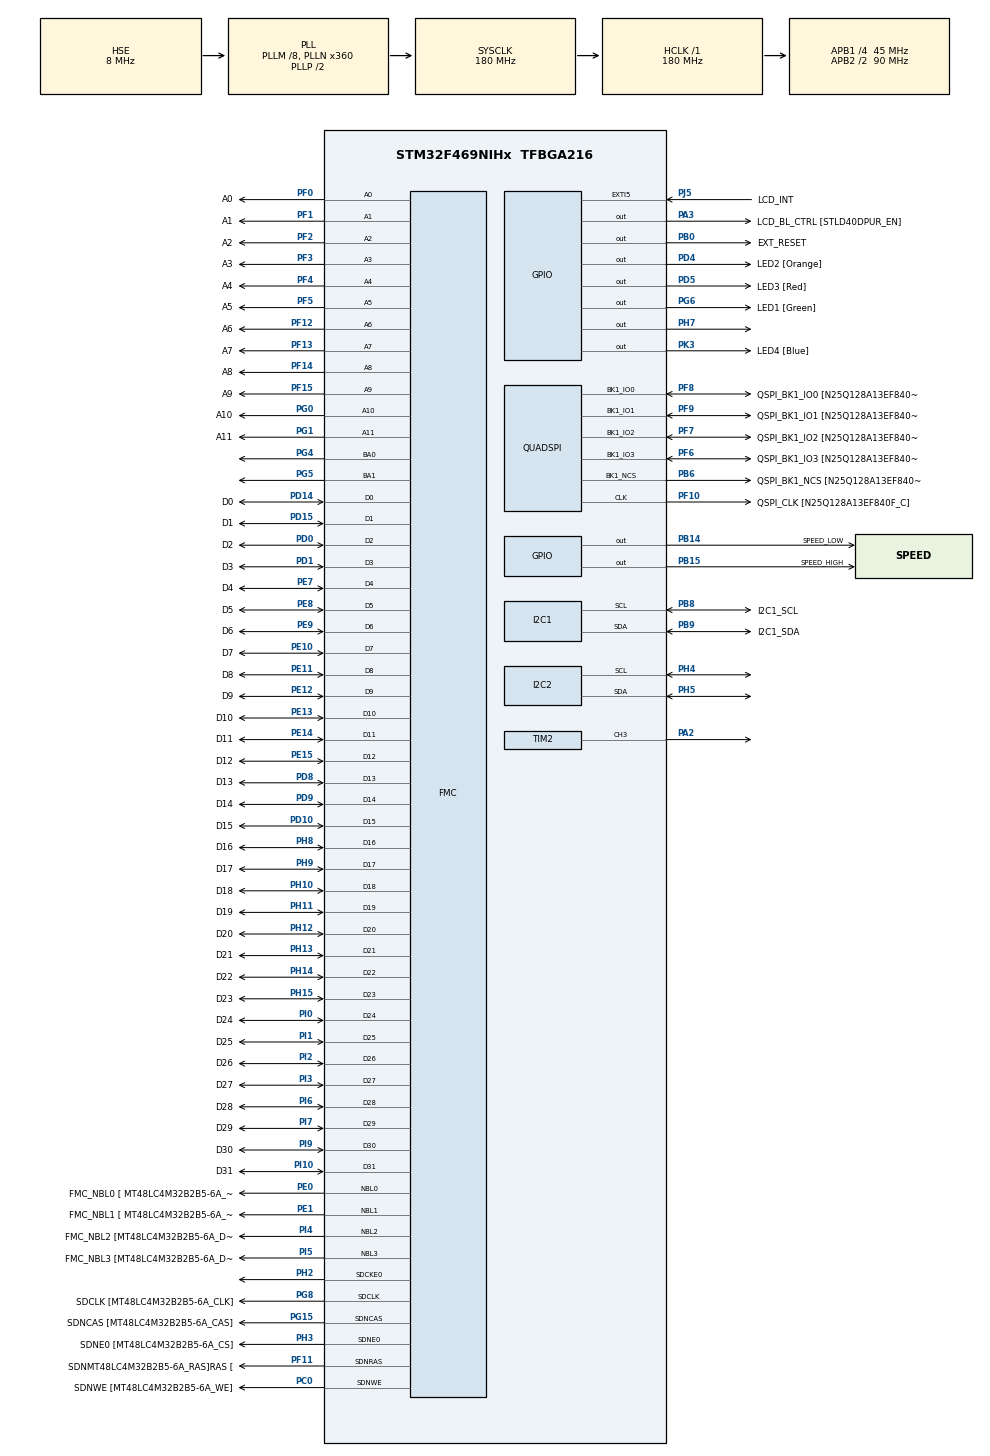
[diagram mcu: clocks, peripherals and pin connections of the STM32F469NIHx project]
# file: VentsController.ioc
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DSIHOST.NumberOfLanes=DSI_TWO_DATA_LANES
DSIHOST.StopWaitTime=10
DSIHOST_CKN.GPIO_Label=DSI_CK_N
DSIHOST_CKN.Mode=DSIHost_Video
DSIHOST_CKN.Signal=DSIHOST_CKN
DSIHOST_CKP.GPIO_Label=DSI_CK_P
DSIHOST_CKP.Mode=DSIHost_Video
DSIHOST_CKP.Signal=DSIHOST_CKP
DSIHOST_D0N.GPIO_Label=DSI_D0_N
DSIHOST_D0N.Mode=DSIHost_Video
DSIHOST_D0N.Signal=DSIHOST_D0N
DSIHOST_D0P.GPIO_Label=DSI_D0_P
DSIHOST_D0P.Mode=DSIHost_Video
DSIHOST_D0P.Signal=DSIHOST_D0P
DSIHOST_D1N.GPIO_Label=DSI_D1_N
DSIHOST_D1N.Mode=DSIHost_Video
DSIHOST_D1N.Signal=DSIHOST_D1N
DSIHOST_D1P.GPIO_Label=DSI_D1_P
DSIHOST_D1P.Mode=DSIHost_Video
DSIHOST_D1P.Signal=DSIHOST_D1P
FREERTOS.Tasks01=defaultTask,0,4096,StartDefaultTask,Default,NULL,Dynamic,NULL,NULL
FREERTOS.configCHECK_FOR_STACK_OVERFLOW=2
FREERTOS.configTOTAL_HEAP_SIZE=32768
FREERTOS.configUSE_APPLICATION_TASK_TAG=1
FREERTOS.configUSE_COUNTING_SEMAPHORES=1
FREERTOS.configUSE_IDLE_HOOK=1
FREERTOS.configUSE_MALLOC_FAILED_HOOK=1
FREERTOS.configUSE_RECURSIVE_MUTEXES=1
LTDC.ActiveW=800
Mcu.Family=STM32F4
Mcu.Name=STM32F469NIHx
Mcu.Package=TFBGA216
NVIC.DMA2D_IRQn=true\:5\:0\:false\:false\:true\:true\:true\:true
NVIC.DSI_IRQn=true\:5\:0\:false\:false\:true\:true\:true\:true
NVIC.PriorityGroup=NVIC_PRIORITYGROUP_4
NVIC.TIM6_DAC_IRQn=true\:15\:0\:false\:false\:true\:false\:false\:true
NVIC.TimeBase=TIM6_DAC_IRQn
NVIC.TimeBaseIP=TIM6
PA2.Signal=S_TIM2_CH3
PA3.GPIO_Label=LCD_BL_CTRL [STLD40DPUR_EN]
PA3.GPIO_ModeDefaultOutputPP=GPIO_MODE_OUTPUT_PP
PA3.GPIO_PuPd=GPIO_NOPULL
PA3.GPIO_Speed=GPIO_SPEED_FREQ_LOW
PA3.Signal=GPIO_Output
PB0.GPIO_Label=EXT_RESET
PB0.GPIO_ModeDefaultOutputPP=GPIO_MODE_OUTPUT_PP
PB0.GPIO_PuPd=GPIO_NOPULL
PB0.GPIO_Speed=GPIO_SPEED_FREQ_LOW
PB0.Signal=GPIO_Output
PB14.GPIO_Label=SPEED_LOW
PB14.Signal=GPIO_Output
PB15.GPIO_Label=SPEED_HIGH
PB15.Signal=GPIO_Output
PB6.GPIO_Label=QSPI_BK1_NCS [N25Q128A13EF840F_S]
PB6.GPIO_Mode=GPIO_MODE_AF_PP
PB6.GPIO_PuPd=GPIO_NOPULL
PB6.GPIO_Speed=GPIO_SPEED_FREQ_VERY_HIGH
PB6.Mode=Single Bank 1
PB6.Signal=QUADSPI_BK1_NCS
PB8.GPIO_Label=I2C1_SCL
PB8.GPIO_Mode=GPIO_MODE_AF_OD
PB8.GPIO_Pu=GPIO_PULLUP
PB8.GPIO_Speed=GPIO_SPEED_FREQ_VERY_HIGH
PB8.Mode=I2C
PB8.Signal=I2C1_SCL
PB9.GPIO_Label=I2C1_SDA
PB9.GPIO_Mode=GPIO_MODE_AF_OD
PB9.GPIO_Pu=GPIO_PULLUP
PB9.GPIO_Speed=GPIO_SPEED_FREQ_VERY_HIGH
PB9.Mode=I2C
PB9.Signal=I2C1_SDA
PC0.GPIO_Label=SDNWE [MT48LC4M32B2B5-6A_WE]
PC0.GPIO_Mode=GPIO_MODE_AF_PP
PC0.GPIO_PuPd=GPIO_NOPULL
PC0.GPIO_Speed_High_Default=GPIO_SPEED_FREQ_VERY_HIGH
PC0.Signal=FMC_SDNWE
PC14/OSC32_IN.Mode=LSE-External-Oscillator
PC14/OSC32_IN.Signal=RCC_OSC32_IN
PC15/OSC32_OUT.Mode=LSE-External-Oscillator
PC15/OSC32_OUT.Signal=RCC_OSC32_OUT
PD0.GPIO_Label=D2
PD0.GPIO_Mode=GPIO_MODE_AF_PP
PD0.GPIO_PuPd=GPIO_NOPULL
PD0.GPIO_Speed_High_Default=GPIO_SPEED_FREQ_VERY_HIGH
PD0.Signal=FMC_D2_DA2
PD1.GPIO_Label=D3
PD1.GPIO_Mode=GPIO_MODE_AF_PP
PD1.GPIO_PuPd=GPIO_NOPULL
PD1.GPIO_Speed_High_Default=GPIO_SPEED_FREQ_VERY_HIGH
PD1.Signal=FMC_D3_DA3
PD10.GPIO_Label=D15
PD10.GPIO_Mode=GPIO_MODE_AF_PP
PD10.GPIO_PuPd=GPIO_NOPULL
PD10.GPIO_Speed_High_Default=GPIO_SPEED_FREQ_VERY_HIGH
PD10.Signal=FMC_D15_DA15
PD14.GPIO_Label=D0
PD14.GPIO_Mode=GPIO_MODE_AF_PP
PD14.GPIO_PuPd=GPIO_NOPULL
PD14.GPIO_Speed_High_Default=GPIO_SPEED_FREQ_VERY_HIGH
PD14.Signal=FMC_D0_DA0
PD15.GPIO_Label=D1
PD15.GPIO_Mode=GPIO_MODE_AF_PP
PD15.GPIO_PuPd=GPIO_NOPULL
PD15.GPIO_Speed_High_Default=GPIO_SPEED_FREQ_VERY_HIGH
PD15.Signal=FMC_D1_DA1
PD4.GPIO_Label=LED2 [Orange]
PD4.GPIO_ModeDefaultOutputPP=GPIO_MODE_OUTPUT_OD
PD4.GPIO_PuPd=GPIO_NOPULL
PD4.GPIO_Speed=GPIO_SPEED_FREQ_LOW
PD4.Signal=GPIO_Output
PD5.GPIO_Label=LED3 [Red]
PD5.GPIO_ModeDefaultOutputPP=GPIO_MODE_OUTPUT_OD
PD5.GPIO_PuPd=GPIO_NOPULL
PD5.GPIO_Speed=GPIO_SPEED_FREQ_LOW
PD5.Signal=GPIO_Output
PD8.GPIO_Label=D13
PD8.GPIO_Mode=GPIO_MODE_AF_PP
PD8.GPIO_PuPd=GPIO_NOPULL
PD8.GPIO_Speed_High_Default=GPIO_SPEED_FREQ_VERY_HIGH
PD8.Signal=FMC_D13_DA13
PD9.GPIO_Label=D14
PD9.GPIO_Mode=GPIO_MODE_AF_PP
PD9.GPIO_PuPd=GPIO_NOPULL
PD9.GPIO_Speed_High_Default=GPIO_SPEED_FREQ_VERY_HIGH
PD9.Signal=FMC_D14_DA14
PE0.GPIO_Label=FMC_NBL0 [ MT48LC4M32B2B5-6A_DQM0]
PE0.GPIO_Mode=GPIO_MODE_AF_PP
PE0.GPIO_PuPd=GPIO_NOPULL
PE0.GPIO_Speed_High_Default=GPIO_SPEED_FREQ_VERY_HIGH
PE0.Signal=FMC_NBL0
PE1.GPIO_Label=FMC_NBL1 [ MT48LC4M32B2B5-6A_DQM1]
PE1.GPIO_Mode=GPIO_MODE_AF_PP
PE1.GPIO_PuPd=GPIO_NOPULL
PE1.GPIO_Speed_High_Default=GPIO_SPEED_FREQ_VERY_HIGH
PE1.Signal=FMC_NBL1
PE10.GPIO_Label=D7
PE10.GPIO_Mode=GPIO_MODE_AF_PP
PE10.GPIO_PuPd=GPIO_NOPULL
PE10.GPIO_Speed_High_Default=GPIO_SPEED_FREQ_VERY_HIGH
PE10.Signal=FMC_D7_DA7
PE11.GPIO_Label=D8
PE11.GPIO_Mode=GPIO_MODE_AF_PP
PE11.GPIO_PuPd=GPIO_NOPULL
PE11.GPIO_Speed_High_Default=GPIO_SPEED_FREQ_VERY_HIGH
PE11.Signal=FMC_D8_DA8
PE12.GPIO_Label=D9
PE12.GPIO_Mode=GPIO_MODE_AF_PP
PE12.GPIO_PuPd=GPIO_NOPULL
PE12.GPIO_Speed_High_Default=GPIO_SPEED_FREQ_VERY_HIGH
PE12.Signal=FMC_D9_DA9
PE13.GPIO_Label=D10
PE13.GPIO_Mode=GPIO_MODE_AF_PP
PE13.GPIO_PuPd=GPIO_NOPULL
PE13.GPIO_Speed_High_Default=GPIO_SPEED_FREQ_VERY_HIGH
PE13.Signal=FMC_D10_DA10
PE14.GPIO_Label=D11
PE14.GPIO_Mode=GPIO_MODE_AF_PP
PE14.GPIO_PuPd=GPIO_NOPULL
PE14.GPIO_Speed_High_Default=GPIO_SPEED_FREQ_VERY_HIGH
PE14.Signal=FMC_D11_DA11
PE15.GPIO_Label=D12
PE15.GPIO_Mode=GPIO_MODE_AF_PP
PE15.GPIO_PuPd=GPIO_NOPULL
PE15.GPIO_Speed_High_Default=GPIO_SPEED_FREQ_VERY_HIGH
PE15.Signal=FMC_D12_DA12
PE7.GPIO_Label=D4
PE7.GPIO_Mode=GPIO_MODE_AF_PP
PE7.GPIO_PuPd=GPIO_NOPULL
PE7.GPIO_Speed_High_Default=GPIO_SPEED_FREQ_VERY_HIGH
PE7.Signal=FMC_D4_DA4
PE8.GPIO_Label=D5
PE8.GPIO_Mode=GPIO_MODE_AF_PP
PE8.GPIO_PuPd=GPIO_NOPULL
PE8.GPIO_Speed_High_Default=GPIO_SPEED_FREQ_VERY_HIGH
PE8.Signal=FMC_D5_DA5
PE9.GPIO_Label=D6
PE9.GPIO_Mode=GPIO_MODE_AF_PP
PE9.GPIO_PuPd=GPIO_NOPULL
PE9.GPIO_Speed_High_Default=GPIO_SPEED_FREQ_VERY_HIGH
PE9.Signal=FMC_D6_DA6
PF0.GPIO_Label=A0
PF0.GPIO_Mode=GPIO_MODE_AF_PP
PF0.GPIO_PuPd=GPIO_NOPULL
PF0.GPIO_Speed_High_Default=GPIO_SPEED_FREQ_VERY_HIGH
PF0.Signal=FMC_A0
PF1.GPIO_Label=A1
PF1.GPIO_Mode=GPIO_MODE_AF_PP
PF1.GPIO_PuPd=GPIO_NOPULL
PF1.GPIO_Speed_High_Default=GPIO_SPEED_FREQ_VERY_HIGH
PF1.Signal=FMC_A1
PF10.GPIO_Label=QSPI_CLK [N25Q128A13EF840F_C]
PF10.GPIO_Mode=GPIO_MODE_AF_PP
PF10.GPIO_PuPd=GPIO_NOPULL
PF10.GPIO_Speed=GPIO_SPEED_FREQ_VERY_HIGH
PF10.Mode=Single Bank 1
PF10.Signal=QUADSPI_CLK
PF11.GPIO_Label=SDNMT48LC4M32B2B5-6A_RAS]RAS [
PF11.GPIO_Mode=GPIO_MODE_AF_PP
PF11.GPIO_PuPd=GPIO_NOPULL
PF11.GPIO_Speed_High_Default=GPIO_SPEED_FREQ_VERY_HIGH
PF11.Signal=FMC_SDNRAS
PF12.GPIO_Label=A6
PF12.GPIO_Mode=GPIO_MODE_AF_PP
PF12.GPIO_PuPd=GPIO_NOPULL
PF12.GPIO_Speed_High_Default=GPIO_SPEED_FREQ_VERY_HIGH
PF12.Signal=FMC_A6
PF13.GPIO_Label=A7
PF13.GPIO_Mode=GPIO_MODE_AF_PP
PF13.GPIO_PuPd=GPIO_NOPULL
PF13.GPIO_Speed_High_Default=GPIO_SPEED_FREQ_VERY_HIGH
PF13.Signal=FMC_A7
PF14.GPIO_Label=A8
PF14.GPIO_Mode=GPIO_MODE_AF_PP
PF14.GPIO_PuPd=GPIO_NOPULL
PF14.GPIO_Speed_High_Default=GPIO_SPEED_FREQ_VERY_HIGH
PF14.Signal=FMC_A8
PF15.GPIO_Label=A9
PF15.GPIO_Mode=GPIO_MODE_AF_PP
PF15.GPIO_PuPd=GPIO_NOPULL
PF15.GPIO_Speed_High_Default=GPIO_SPEED_FREQ_VERY_HIGH
PF15.Signal=FMC_A9
PF2.GPIO_Label=A2
PF2.GPIO_Mode=GPIO_MODE_AF_PP
PF2.GPIO_PuPd=GPIO_NOPULL
PF2.GPIO_Speed_High_Default=GPIO_SPEED_FREQ_VERY_HIGH
PF2.Signal=FMC_A2
PF3.GPIO_Label=A3
PF3.GPIO_Mode=GPIO_MODE_AF_PP
PF3.GPIO_PuPd=GPIO_NOPULL
PF3.GPIO_Speed_High_Default=GPIO_SPEED_FREQ_VERY_HIGH
PF3.Signal=FMC_A3
PF4.GPIO_Label=A4
PF4.GPIO_Mode=GPIO_MODE_AF_PP
PF4.GPIO_PuPd=GPIO_NOPULL
PF4.GPIO_Speed_High_Default=GPIO_SPEED_FREQ_VERY_HIGH
PF4.Signal=FMC_A4
PF5.GPIO_Label=A5
PF5.GPIO_Mode=GPIO_MODE_AF_PP
PF5.GPIO_PuPd=GPIO_NOPULL
PF5.GPIO_Speed_High_Default=GPIO_SPEED_FREQ_VERY_HIGH
PF5.Signal=FMC_A5
PF6.GPIO_Label=QSPI_BK1_IO3 [N25Q128A13EF840F_DQ3]
PF6.GPIO_Mode=GPIO_MODE_AF_PP
PF6.GPIO_PuPd=GPIO_NOPULL
PF6.GPIO_Speed=GPIO_SPEED_FREQ_VERY_HIGH
PF6.Mode=Single Bank 1
PF6.Signal=QUADSPI_BK1_IO3
PF7.GPIO_Label=QSPI_BK1_IO2 [N25Q128A13EF840F_DQ2]
PF7.GPIO_Mode=GPIO_MODE_AF_PP
PF7.GPIO_PuPd=GPIO_NOPULL
PF7.GPIO_Speed=GPIO_SPEED_FREQ_VERY_HIGH
PF7.Mode=Single Bank 1
PF7.Signal=QUADSPI_BK1_IO2
PF8.GPIO_Label=QSPI_BK1_IO0 [N25Q128A13EF840F_DQ0]
PF8.GPIO_Mode=GPIO_MODE_AF_PP
PF8.GPIO_PuPd=GPIO_NOPULL
PF8.GPIO_Speed=GPIO_SPEED_FREQ_VERY_HIGH
PF8.Mode=Single Bank 1
PF8.Signal=QUADSPI_BK1_IO0
PF9.GPIO_Label=QSPI_BK1_IO1 [N25Q128A13EF840F_DQ1]
PF9.GPIO_Mode=GPIO_MODE_AF_PP
PF9.GPIO_PuPd=GPIO_NOPULL
PF9.GPIO_Speed=GPIO_SPEED_FREQ_VERY_HIGH
PF9.Mode=Single Bank 1
PF9.Signal=QUADSPI_BK1_IO1
PG0.GPIO_Label=A10
PG0.GPIO_Mode=GPIO_MODE_AF_PP
PG0.GPIO_PuPd=GPIO_NOPULL
PG0.GPIO_Speed_High_Default=GPIO_SPEED_FREQ_VERY_HIGH
PG0.Signal=FMC_A10
PG1.GPIO_Label=A11
PG1.GPIO_Mode=GPIO_MODE_AF_PP
PG1.GPIO_PuPd=GPIO_NOPULL
PG1.GPIO_Speed_High_Default=GPIO_SPEED_FREQ_VERY_HIGH
PG1.Signal=FMC_A11
PG15.GPIO_Label=SDNCAS [MT48LC4M32B2B5-6A_CAS]
PG15.GPIO_Mode=GPIO_MODE_AF_PP
PG15.GPIO_PuPd=GPIO_NOPULL
PG15.GPIO_Speed_High_Default=GPIO_SPEED_FREQ_VERY_HIGH
PG15.Signal=FMC_SDNCAS
PG4.Signal=FMC_A14_BA0
PG5.Signal=FMC_A15_BA1
PG6.GPIO_Label=LED1 [Green]
PG6.GPIO_ModeDefaultOutputPP=GPIO_MODE_OUTPUT_OD
PG6.GPIO_PuPd=GPIO_NOPULL
PG6.GPIO_Speed=GPIO_SPEED_FREQ_LOW
PG6.Signal=GPIO_Output
PG8.GPIO_Label=SDCLK [MT48LC4M32B2B5-6A_CLK]
PG8.GPIO_Mode=GPIO_MODE_AF_PP
PG8.GPIO_PuPd=GPIO_NOPULL
PG8.GPIO_Speed_High_Default=GPIO_SPEED_FREQ_VERY_HIGH
PG8.Signal=FMC_SDCLK
PH0/OSC_IN.Mode=HSE-External-Oscillator
PH0/OSC_IN.Signal=RCC_OSC_IN
PH1/OSC_OUT.Mode=HSE-External-Oscillator
PH1/OSC_OUT.Signal=RCC_OSC_OUT
PH10.GPIO_Label=D18
PH10.GPIO_Mode=GPIO_MODE_AF_PP
PH10.GPIO_PuPd=GPIO_NOPULL
PH10.GPIO_Speed_High_Default=GPIO_SPEED_FREQ_VERY_HIGH
PH10.Signal=FMC_D18
PH11.GPIO_Label=D19
PH11.GPIO_Mode=GPIO_MODE_AF_PP
PH11.GPIO_PuPd=GPIO_NOPULL
PH11.GPIO_Speed_High_Default=GPIO_SPEED_FREQ_VERY_HIGH
PH11.Signal=FMC_D19
PH12.GPIO_Label=D20
PH12.GPIO_Mode=GPIO_MODE_AF_PP
PH12.GPIO_PuPd=GPIO_NOPULL
PH12.GPIO_Speed_High_Default=GPIO_SPEED_FREQ_VERY_HIGH
PH12.Signal=FMC_D20
PH13.GPIO_Label=D21
PH13.GPIO_Mode=GPIO_MODE_AF_PP
PH13.GPIO_PuPd=GPIO_NOPULL
PH13.GPIO_Speed_High_Default=GPIO_SPEED_FREQ_VERY_HIGH
PH13.Signal=FMC_D21
PH14.GPIO_Label=D22
PH14.GPIO_Mode=GPIO_MODE_AF_PP
PH14.GPIO_PuPd=GPIO_NOPULL
PH14.GPIO_Speed_High_Default=GPIO_SPEED_FREQ_VERY_HIGH
PH14.Signal=FMC_D22
PH15.GPIO_Label=D23
PH15.GPIO_Mode=GPIO_MODE_AF_PP
PH15.GPIO_PuPd=GPIO_NOPULL
PH15.GPIO_Speed_High_Default=GPIO_SPEED_FREQ_VERY_HIGH
PH15.Signal=FMC_D23
PH2.Mode=SdramChipSelect1_1
PH2.Signal=FMC_SDCKE0
PH3.GPIO_Label=SDNE0 [MT48LC4M32B2B5-6A_CS]
PH3.GPIO_Mode=GPIO_MODE_AF_PP
PH3.GPIO_PuPd=GPIO_NOPULL
PH3.GPIO_Speed_High_Default=GPIO_SPEED_FREQ_VERY_HIGH
PH3.Mode=SdramChipSelect1_1
PH3.Signal=FMC_SDNE0
PH4.Mode=I2C
PH4.Signal=I2C2_SCL
PH5.Mode=I2C
PH5.Signal=I2C2_SDA
PH7.Signal=GPIO_Output
PH8.GPIO_Label=D16
PH8.GPIO_Mode=GPIO_MODE_AF_PP
PH8.GPIO_PuPd=GPIO_NOPULL
PH8.GPIO_Speed_High_Default=GPIO_SPEED_FREQ_VERY_HIGH
PH8.Signal=FMC_D16
PH9.GPIO_Label=D17
PH9.GPIO_Mode=GPIO_MODE_AF_PP
PH9.GPIO_PuPd=GPIO_NOPULL
PH9.GPIO_Speed_High_Default=GPIO_SPEED_FREQ_VERY_HIGH
PH9.Signal=FMC_D17
PI0.GPIO_Label=D24
PI0.GPIO_Mode=GPIO_MODE_AF_PP
PI0.GPIO_PuPd=GPIO_NOPULL
PI0.GPIO_Speed_High_Default=GPIO_SPEED_FREQ_VERY_HIGH
PI0.Signal=FMC_D24
PI1.GPIO_Label=D25
PI1.GPIO_Mode=GPIO_MODE_AF_PP
PI1.GPIO_PuPd=GPIO_NOPULL
PI1.GPIO_Speed_High_Default=GPIO_SPEED_FREQ_VERY_HIGH
PI1.Signal=FMC_D25
PI10.GPIO_Label=D31
PI10.GPIO_Mode=GPIO_MODE_AF_PP
PI10.GPIO_PuPd=GPIO_NOPULL
PI10.GPIO_Speed_High_Default=GPIO_SPEED_FREQ_VERY_HIGH
PI10.Signal=FMC_D31
PI2.GPIO_Label=D26
PI2.GPIO_Mode=GPIO_MODE_AF_PP
PI2.GPIO_PuPd=GPIO_NOPULL
PI2.GPIO_Speed_High_Default=GPIO_SPEED_FREQ_VERY_HIGH
PI2.Signal=FMC_D26
PI3.GPIO_Label=D27
PI3.GPIO_Mode=GPIO_MODE_AF_PP
PI3.GPIO_PuPd=GPIO_NOPULL
PI3.GPIO_Speed_High_Default=GPIO_SPEED_FREQ_VERY_HIGH
PI3.Signal=FMC_D27
PI4.GPIO_Label=FMC_NBL2 [MT48LC4M32B2B5-6A_DQM2]
PI4.GPIO_Mode=GPIO_MODE_AF_PP
PI4.GPIO_PuPd=GPIO_NOPULL
PI4.GPIO_Speed_High_Default=GPIO_SPEED_FREQ_VERY_HIGH
PI4.Signal=FMC_NBL2
PI5.GPIO_Label=FMC_NBL3 [MT48LC4M32B2B5-6A_DQM3]
PI5.GPIO_Mode=GPIO_MODE_AF_PP
PI5.GPIO_PuPd=GPIO_NOPULL
PI5.GPIO_Speed_High_Default=GPIO_SPEED_FREQ_VERY_HIGH
PI5.Signal=FMC_NBL3
PI6.GPIO_Label=D28
PI6.GPIO_Mode=GPIO_MODE_AF_PP
PI6.GPIO_PuPd=GPIO_NOPULL
PI6.GPIO_Speed_High_Default=GPIO_SPEED_FREQ_VERY_HIGH
PI6.Signal=FMC_D28
PI7.GPIO_Label=D29
PI7.GPIO_Mode=GPIO_MODE_AF_PP
PI7.GPIO_PuPd=GPIO_NOPULL
PI7.GPIO_Speed_High_Default=GPIO_SPEED_FREQ_VERY_HIGH
PI7.Signal=FMC_D29
PI9.GPIO_Label=D30
PI9.GPIO_Mode=GPIO_MODE_AF_PP
PI9.GPIO_PuPd=GPIO_NOPULL
PI9.GPIO_Speed_High_Default=GPIO_SPEED_FREQ_VERY_HIGH
PI9.Signal=FMC_D30
PJ5.GPIO_Label=LCD_INT
PJ5.GPIO_ModeDefaultEXTI=GPIO_MODE_IT_RISING
PJ5.GPIO_PuPd=GPIO_NOPULL
PJ5.Signal=GPXTI5
PK3.GPIO_Label=LED4 [Blue]
PK3.GPIO_ModeDefaultOutputPP=GPIO_MODE_OUTPUT_OD
PK3.GPIO_PuPd=GPIO_NOPULL
PK3.GPIO_Speed=GPIO_SPEED_FREQ_LOW
PK3.Signal=GPIO_Output
ProjectManager.HeapSize=0x200
ProjectManager.StackSize=0x400
ProjectManager.TargetToolchain=STM32CubeIDE
QUADSPI.ChipSelectHighTime=QSPI_CS_HIGH_TIME_5_CYCLE
QUADSPI.ClockPrescaler=1
QUADSPI.FifoThreshold=1
QUADSPI.FlashSize=27
QUADSPI.SampleShifting=QSPI_SAMPLE_SHIFTING_HALFCYCLE
RCC.AHBFreq_Value=180000000
RCC.APB1CLKDivider=RCC_HCLK_DIV4
RCC.APB1Freq_Value=45000000
RCC.APB1TimFreq_Value=90000000
RCC.APB2CLKDivider=RCC_HCLK_DIV2
RCC.APB2Freq_Value=90000000
RCC.APB2TimFreq_Value=180000000
RCC.CortexFreq_Value=180000000
RCC.HCLKFreq_Value=180000000
RCC.HSE_VALUE=8000000
RCC.PLLDSIIDF=DSI_PLL_IN_DIV2
RCC.PLLDSINDIV=125
RCC.PLLM=8
RCC.PLLN=360
RCC.PLLR=6
RCC.PLLSAIN=360
RCC.PLLSAIP=RCC_PLLSAIP_DIV6
RCC.PLLSAIQ=2
RCC.PLLSAIR=6
RCC.PLLSourceVirtual=RCC_PLLSOURCE_HSE
RCC.SYSCLKFreq_VALUE=180000000
RCC.SYSCLKSource=RCC_SYSCLKSOURCE_PLLCLK
RCC.USBCLockSelection=RCC_CLK48CLKSOURCE_PLLSAIP
RCC.USBFreq_Value=60000000
RCC.VCOOutputFreq_Value=360000000
SH.FMC_A0.0=FMC_A0,12b-sda1
SH.FMC_A1.0=FMC_A1,12b-sda1
SH.FMC_A10.0=FMC_A10,12b-sda1
SH.FMC_A11.0=FMC_A11,12b-sda1
SH.FMC_A14_BA0.0=FMC_BA0,FourSdramBanks1
SH.FMC_A15_BA1.0=FMC_BA1,FourSdramBanks1
SH.FMC_A2.0=FMC_A2,12b-sda1
SH.FMC_A3.0=FMC_A3,12b-sda1
SH.FMC_A4.0=FMC_A4,12b-sda1
SH.FMC_A5.0=FMC_A5,12b-sda1
SH.FMC_A6.0=FMC_A6,12b-sda1
SH.FMC_A7.0=FMC_A7,12b-sda1
SH.FMC_A8.0=FMC_A8,12b-sda1
SH.FMC_A9.0=FMC_A9,12b-sda1
SH.FMC_D0_DA0.0=FMC_D0,sd-32b-d1
SH.FMC_D10_DA10.0=FMC_D10,sd-32b-d1
SH.FMC_D11_DA11.0=FMC_D11,sd-32b-d1
SH.FMC_D12_DA12.0=FMC_D12,sd-32b-d1
SH.FMC_D13_DA13.0=FMC_D13,sd-32b-d1
SH.FMC_D14_DA14.0=FMC_D14,sd-32b-d1
SH.FMC_D15_DA15.0=FMC_D15,sd-32b-d1
SH.FMC_D16.0=FMC_D16,sd-32b-d1
SH.FMC_D17.0=FMC_D17,sd-32b-d1
SH.FMC_D18.0=FMC_D18,sd-32b-d1
SH.FMC_D19.0=FMC_D19,sd-32b-d1
SH.FMC_D1_DA1.0=FMC_D1,sd-32b-d1
SH.FMC_D20.0=FMC_D20,sd-32b-d1
SH.FMC_D21.0=FMC_D21,sd-32b-d1
SH.FMC_D22.0=FMC_D22,sd-32b-d1
SH.FMC_D23.0=FMC_D23,sd-32b-d1
SH.FMC_D24.0=FMC_D24,sd-32b-d1
SH.FMC_D25.0=FMC_D25,sd-32b-d1
SH.FMC_D26.0=FMC_D26,sd-32b-d1
SH.FMC_D27.0=FMC_D27,sd-32b-d1
SH.FMC_D28.0=FMC_D28,sd-32b-d1
SH.FMC_D29.0=FMC_D29,sd-32b-d1
SH.FMC_D2_DA2.0=FMC_D2,sd-32b-d1
SH.FMC_D30.0=FMC_D30,sd-32b-d1
SH.FMC_D31.0=FMC_D31,sd-32b-d1
SH.FMC_D3_DA3.0=FMC_D3,sd-32b-d1
SH.FMC_D4_DA4.0=FMC_D4,sd-32b-d1
SH.FMC_D5_DA5.0=FMC_D5,sd-32b-d1
SH.FMC_D6_DA6.0=FMC_D6,sd-32b-d1
SH.FMC_D7_DA7.0=FMC_D7,sd-32b-d1
SH.FMC_D8_DA8.0=FMC_D8,sd-32b-d1
SH.FMC_D9_DA9.0=FMC_D9,sd-32b-d1
SH.FMC_NBL0.0=FMC_NBL0,Sd4ByteEnable1
SH.FMC_NBL1.0=FMC_NBL1,Sd4ByteEnable1
SH.FMC_NBL2.0=FMC_NBL2,Sd4ByteEnable1
SH.FMC_NBL3.0=FMC_NBL3,Sd4ByteEnable1
SH.FMC_SDCLK.0=FMC_SDCLK,12b-sda1
SH.FMC_SDNCAS.0=FMC_SDNCAS,12b-sda1
SH.FMC_SDNRAS.0=FMC_SDNRAS,12b-sda1
SH.FMC_SDNWE.0=FMC_SDNWE,12b-sda1
SH.S_TIM2_CH3.0=TIM2_CH3,PWM Generation3 CH3
TIM2.Channel-PWM\ Generation3\ CH3=TIM_CHANNEL_3
TIM2.Period=50
TIM2.Prescaler=180-1
VP_CRC_VS_CRC.Mode=CRC_Activate
VP_DMA2D_VS_DMA2D.Mode=DMA2D_Activate
VP_FREERTOS_VS_CMSIS_V1.Mode=CMSIS_V1
VP_LTDC_DSIMode.Mode=RGB565
VP_SYS_VS_tim6.Mode=TIM6
VP_TIM2_VS_ClockSourceINT.Mode=Internal
board=STM32F469I-DISCO

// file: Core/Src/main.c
/* USER CODE BEGIN Header */
/**
  ******************************************************************************
  * @file           : main.c
  * @brief          : Main program body
  ******************************************************************************
  * @attention
  *
  * <h2><center>&copy; Copyright (c) 2021 STMicroelectronics.
  * All rights reserved.</center></h2>
  *
  * This software component is licensed by ST under Ultimate Liberty license
  * SLA0044, the "License"; You may not use this file except in compliance with
  * the License. You may obtain a copy of the License at:
  *                             www.st.com/SLA0044
  *
  ******************************************************************************
  */
/* USER CODE END Header */
#include "main.h"
#include "cmsis_os.h"

/* USER CODE BEGIN Includes */
#include "../lvgl/lvgl.h"

#include "../hal_stm_lvgl/tft/tft.h"
#include "../hal_stm_lvgl/touchpad/touchpad.h"

#include "../lv_examples/lv_examples.h"
/* USER CODE END Includes */

CRC_HandleTypeDef hcrc;

DMA2D_HandleTypeDef hdma2d;

DSI_HandleTypeDef hdsi;

I2C_HandleTypeDef hi2c1;
I2C_HandleTypeDef hi2c2;

LTDC_HandleTypeDef hltdc;

QSPI_HandleTypeDef hqspi;

TIM_HandleTypeDef htim2;

SDRAM_HandleTypeDef hsdram1;

osThreadId defaultTaskHandle;

void SystemClock_Config(void);
static void MX_GPIO_Init(void);
static void MX_CRC_Init(void);
static void MX_DMA2D_Init(void);
static void MX_DSIHOST_DSI_Init(void);
static void MX_FMC_Init(void);
static void MX_I2C1_Init(void);
static void MX_LTDC_Init(void);
static void MX_QUADSPI_Init(void);
static void MX_I2C2_Init(void);
static void MX_TIM2_Init(void);
void StartDefaultTask(void const * argument);

/* USER CODE BEGIN 0 */
static void btn_enable_low_level(lv_obj_t * btn, lv_event_t event)
{
    if(event == LV_EVENT_CLICKED) {
        HAL_GPIO_WritePin(LED2_GPIO_Port, LED2_Pin, GPIO_PIN_RESET);
        TIM2->CCR3 = 30;
    }
}

void lv_ex_low_btn(void)
{
    lv_obj_t * btn = lv_btn_create(lv_scr_act(), NULL);     /*Add a button the current screen*/
    lv_obj_set_pos(btn, 150, 100);                            /*Set its position*/
    lv_obj_set_size(btn, 220, 100);                          /*Set its size*/
    lv_obj_set_event_cb(btn, btn_enable_low_level);                 /*Assign a callback to the button*/

    lv_obj_t * label = lv_label_create(btn, NULL);          /*Add a label to the button*/
    lv_label_set_text(label, "Low Level");                     /*Set the labels text*/
}

static void btn_enable_high_level(lv_obj_t * btn, lv_event_t event)
{
    if(event == LV_EVENT_CLICKED) {
        HAL_GPIO_WritePin(LED2_GPIO_Port, LED2_Pin, GPIO_PIN_SET);
        TIM2->CCR3 = 100;
    }
}

static void arc_change(lv_obj_t * btn, lv_event_t event)
{
    if(event == LV_EVENT_VALUE_CHANGED ) {
        HAL_GPIO_WritePin(LED2_GPIO_Port, LED2_Pin, GPIO_PIN_SET);
        TIM2->CCR3 = 100;
    }
}

void power_meter(void)
{
  /*Create an Arc*/
  lv_obj_t * arc = lv_arc_create(lv_scr_act(), NULL);
  lv_arc_set_end_angle(arc, 200);
  lv_obj_set_size(arc, 350, 150);
  //lv_obj_align(arc, NULL, LV_ALIGN_CENTER, 150, 100);

  lv_obj_set_event_cb(arc, arc_change);
}

/**
 * Create a button with a label and react on Click event.
 */
void lv_ex_high_btn(void)
{
    lv_obj_t * btn = lv_btn_create(lv_scr_act(), NULL);     /*Add a button the current screen*/
    lv_obj_set_pos(btn, 450, 100);                            /*Set its position*/
    lv_obj_set_size(btn, 220, 100);                          /*Set its size*/
    lv_obj_set_event_cb(btn, btn_enable_high_level);                 /*Assign a callback to the button*/

    lv_obj_t * label = lv_label_create(btn, NULL);          /*Add a label to the button*/
    lv_label_set_text(label, "High Level");                     /*Set the labels text*/
}
/* USER CODE END 0 */

int main(void)
{

  /* MCU Configuration--------------------------------------------------------*/

  /* Reset of all peripherals, Initializes the Flash interface and the Systick. */
  HAL_Init();

  /* Configure the system clock */
  SystemClock_Config();

  /* Initialize all configured peripherals */
  MX_GPIO_Init();
  MX_CRC_Init();
  MX_DMA2D_Init();
  MX_DSIHOST_DSI_Init();
  MX_FMC_Init();
  MX_I2C1_Init();
  MX_LTDC_Init();
  MX_QUADSPI_Init();
  MX_I2C2_Init();
  MX_TIM2_Init();
  /* USER CODE BEGIN 2 */

  lv_init();
  tft_init();
  touchpad_init();
  lv_ex_low_btn();
  lv_ex_high_btn();
  power_meter();

  TIM2->CCR3 = 0;
  HAL_TIM_PWM_Start(&htim2, TIM_CHANNEL_3);

    //_write(file, ptr, len)
    //lv_demo_printer();
    //lv_demo_music();
    //lv_demo_widgets();
  /* USER CODE END 2 */

  /* Create the thread(s) */
  /* definition and creation of defaultTask */
  osThreadDef(defaultTask, StartDefaultTask, osPriorityNormal, 0, 4096);
  defaultTaskHandle = osThreadCreate(osThread(defaultTask), NULL);

  /* Start scheduler */
  osKernelStart();

  /* We should never get here as control is now taken by the scheduler */
  /* Infinite loop */
  while (1)
  {

  }
}

void SystemClock_Config(void)
{
  RCC_OscInitTypeDef RCC_OscInitStruct = {0};
  RCC_ClkInitTypeDef RCC_ClkInitStruct = {0};

  /** Configure the main internal regulator output voltage
  */
  __HAL_RCC_PWR_CLK_ENABLE();
  __HAL_PWR_VOLTAGESCALING_CONFIG(PWR_REGULATOR_VOLTAGE_SCALE1);
  /** Initializes the RCC Oscillators according to the specified parameters
  * in the RCC_OscInitTypeDef structure.
  */
  RCC_OscInitStruct.OscillatorType = RCC_OSCILLATORTYPE_HSE;
  RCC_OscInitStruct.HSEState = RCC_HSE_ON;
  RCC_OscInitStruct.PLL.PLLState = RCC_PLL_ON;
  RCC_OscInitStruct.PLL.PLLSource = RCC_PLLSOURCE_HSE;
  RCC_OscInitStruct.PLL.PLLM = 8;
  RCC_OscInitStruct.PLL.PLLN = 360;
  RCC_OscInitStruct.PLL.PLLP = RCC_PLLP_DIV2;
  RCC_OscInitStruct.PLL.PLLQ = 4;
  RCC_OscInitStruct.PLL.PLLR = 6;
  if (HAL_RCC_OscConfig(&RCC_OscInitStruct) != HAL_OK)
  {
    Error_Handler();
  }
  /** Activate the Over-Drive mode
  */
  if (HAL_PWREx_EnableOverDrive() != HAL_OK)
  {
    Error_Handler();
  }
  /** Initializes the CPU, AHB and APB buses clocks
  */
  RCC_ClkInitStruct.ClockType = RCC_CLOCKTYPE_HCLK|RCC_CLOCKTYPE_SYSCLK
                              |RCC_CLOCKTYPE_PCLK1|RCC_CLOCKTYPE_PCLK2;
  RCC_ClkInitStruct.SYSCLKSource = RCC_SYSCLKSOURCE_PLLCLK;
  RCC_ClkInitStruct.AHBCLKDivider = RCC_SYSCLK_DIV1;
  RCC_ClkInitStruct.APB1CLKDivider = RCC_HCLK_DIV4;
  RCC_ClkInitStruct.APB2CLKDivider = RCC_HCLK_DIV2;

  if (HAL_RCC_ClockConfig(&RCC_ClkInitStruct, FLASH_LATENCY_5) != HAL_OK)
  {
    Error_Handler();
  }
}

static void MX_CRC_Init(void)
{

  hcrc.Instance = CRC;
  if (HAL_CRC_Init(&hcrc) != HAL_OK)
  {
    Error_Handler();
  }

}

static void MX_DMA2D_Init(void)
{

  hdma2d.Instance = DMA2D;
  hdma2d.Init.Mode = DMA2D_M2M;
  hdma2d.Init.ColorMode = DMA2D_OUTPUT_ARGB8888;
  hdma2d.Init.OutputOffset = 0;
  hdma2d.LayerCfg[1].InputOffset = 0;
  hdma2d.LayerCfg[1].InputColorMode = DMA2D_INPUT_ARGB8888;
  hdma2d.LayerCfg[1].AlphaMode = DMA2D_NO_MODIF_ALPHA;
  hdma2d.LayerCfg[1].InputAlpha = 0;
  if (HAL_DMA2D_Init(&hdma2d) != HAL_OK)
  {
    Error_Handler();
  }
  if (HAL_DMA2D_ConfigLayer(&hdma2d, 1) != HAL_OK)
  {
    Error_Handler();
  }

}

static void MX_DSIHOST_DSI_Init(void)
{

  DSI_PLLInitTypeDef PLLInit = {0};
  DSI_HOST_TimeoutTypeDef HostTimeouts = {0};
  DSI_PHY_TimerTypeDef PhyTimings = {0};
  DSI_VidCfgTypeDef VidCfg = {0};

  hdsi.Instance = DSI;
  hdsi.Init.AutomaticClockLaneControl = DSI_AUTO_CLK_LANE_CTRL_DISABLE;
  hdsi.Init.TXEscapeCkdiv = 4;
  hdsi.Init.NumberOfLanes = DSI_TWO_DATA_LANES;
  PLLInit.PLLNDIV = 125;
  PLLInit.PLLIDF = DSI_PLL_IN_DIV2;
  PLLInit.PLLODF = DSI_PLL_OUT_DIV1;
  if (HAL_DSI_Init(&hdsi, &PLLInit) != HAL_OK)
  {
    Error_Handler();
  }
  HostTimeouts.TimeoutCkdiv = 1;
  HostTimeouts.HighSpeedTransmissionTimeout = 0;
  HostTimeouts.LowPowerReceptionTimeout = 0;
  HostTimeouts.HighSpeedReadTimeout = 0;
  HostTimeouts.LowPowerReadTimeout = 0;
  HostTimeouts.HighSpeedWriteTimeout = 0;
  HostTimeouts.HighSpeedWritePrespMode = DSI_HS_PM_DISABLE;
  HostTimeouts.LowPowerWriteTimeout = 0;
  HostTimeouts.BTATimeout = 0;
  if (HAL_DSI_ConfigHostTimeouts(&hdsi, &HostTimeouts) != HAL_OK)
  {
    Error_Handler();
  }
  PhyTimings.ClockLaneHS2LPTime = 28;
  PhyTimings.ClockLaneLP2HSTime = 33;
  PhyTimings.DataLaneHS2LPTime = 15;
  PhyTimings.DataLaneLP2HSTime = 25;
  PhyTimings.DataLaneMaxReadTime = 0;
  PhyTimings.StopWaitTime = 10;
  if (HAL_DSI_ConfigPhyTimer(&hdsi, &PhyTimings) != HAL_OK)
  {
    Error_Handler();
  }
  if (HAL_DSI_ConfigFlowControl(&hdsi, DSI_FLOW_CONTROL_BTA) != HAL_OK)
  {
    Error_Handler();
  }
  if (HAL_DSI_SetLowPowerRXFilter(&hdsi, 10000) != HAL_OK)
  {
    Error_Handler();
  }
  if (HAL_DSI_ConfigErrorMonitor(&hdsi, HAL_DSI_ERROR_NONE) != HAL_OK)
  {
    Error_Handler();
  }
  VidCfg.VirtualChannelID = 0;
  VidCfg.ColorCoding = DSI_RGB565;
  VidCfg.LooselyPacked = DSI_LOOSELY_PACKED_DISABLE;
  VidCfg.Mode = DSI_VID_MODE_NB_PULSES;
  VidCfg.PacketSize = 1;
  VidCfg.NumberOfChunks = 800;
  VidCfg.NullPacketSize = 0;
  VidCfg.HSPolarity = DSI_HSYNC_ACTIVE_LOW;
  VidCfg.VSPolarity = DSI_VSYNC_ACTIVE_LOW;
  VidCfg.DEPolarity = DSI_DATA_ENABLE_ACTIVE_HIGH;
  VidCfg.HorizontalSyncActive = 17;
  VidCfg.HorizontalBackPorch = 15;
  VidCfg.HorizontalLine = 1710;
  VidCfg.VerticalSyncActive = 4;
  VidCfg.VerticalBackPorch = 2;
  VidCfg.VerticalFrontPorch = 2;
  VidCfg.VerticalActive = 480;
  VidCfg.LPCommandEnable = DSI_LP_COMMAND_DISABLE;
  VidCfg.LPLargestPacketSize = 0;
  VidCfg.LPVACTLargestPacketSize = 0;
  VidCfg.LPHorizontalFrontPorchEnable = DSI_LP_HFP_DISABLE;
  VidCfg.LPHorizontalBackPorchEnable = DSI_LP_HBP_DISABLE;
  VidCfg.LPVerticalActiveEnable = DSI_LP_VACT_DISABLE;
  VidCfg.LPVerticalFrontPorchEnable = DSI_LP_VFP_DISABLE;
  VidCfg.LPVerticalBackPorchEnable = DSI_LP_VBP_DISABLE;
  VidCfg.LPVerticalSyncActiveEnable = DSI_LP_VSYNC_DISABLE;
  VidCfg.FrameBTAAcknowledgeEnable = DSI_FBTAA_DISABLE;
  if (HAL_DSI_ConfigVideoMode(&hdsi, &VidCfg) != HAL_OK)
  {
    Error_Handler();
  }
  if (HAL_DSI_SetGenericVCID(&hdsi, 0) != HAL_OK)
  {
    Error_Handler();
  }

}

static void MX_I2C1_Init(void)
{

  hi2c1.Instance = I2C1;
  hi2c1.Init.ClockSpeed = 100000;
  hi2c1.Init.DutyCycle = I2C_DUTYCYCLE_2;
  hi2c1.Init.OwnAddress1 = 0;
  hi2c1.Init.AddressingMode = I2C_ADDRESSINGMODE_7BIT;
  hi2c1.Init.DualAddressMode = I2C_DUALADDRESS_DISABLE;
  hi2c1.Init.OwnAddress2 = 0;
  hi2c1.Init.GeneralCallMode = I2C_GENERALCALL_DISABLE;
  hi2c1.Init.NoStretchMode = I2C_NOSTRETCH_DISABLE;
  if (HAL_I2C_Init(&hi2c1) != HAL_OK)
  {
    Error_Handler();
  }

}

static void MX_I2C2_Init(void)
{

  hi2c2.Instance = I2C2;
  hi2c2.Init.ClockSpeed = 100000;
  hi2c2.Init.DutyCycle = I2C_DUTYCYCLE_2;
  hi2c2.Init.OwnAddress1 = 0;
  hi2c2.Init.AddressingMode = I2C_ADDRESSINGMODE_7BIT;
  hi2c2.Init.DualAddressMode = I2C_DUALADDRESS_DISABLE;
  hi2c2.Init.OwnAddress2 = 0;
  hi2c2.Init.GeneralCallMode = I2C_GENERALCALL_DISABLE;
  hi2c2.Init.NoStretchMode = I2C_NOSTRETCH_DISABLE;
  if (HAL_I2C_Init(&hi2c2) != HAL_OK)
  {
    Error_Handler();
  }

}

static void MX_LTDC_Init(void)
{

  LTDC_LayerCfgTypeDef pLayerCfg = {0};
  LTDC_LayerCfgTypeDef pLayerCfg1 = {0};

  hltdc.Instance = LTDC;
  hltdc.Init.HSPolarity = LTDC_HSPOLARITY_AL;
  hltdc.Init.VSPolarity = LTDC_VSPOLARITY_AL;
  hltdc.Init.DEPolarity = LTDC_DEPOLARITY_AL;
  hltdc.Init.PCPolarity = LTDC_PCPOLARITY_IPC;
  hltdc.Init.HorizontalSync = 7;
  hltdc.Init.VerticalSync = 3;
  hltdc.Init.AccumulatedHBP = 14;
  hltdc.Init.AccumulatedVBP = 5;
  hltdc.Init.AccumulatedActiveW = 814;
  hltdc.Init.AccumulatedActiveH = 485;
  hltdc.Init.TotalWidth = 820;
  hltdc.Init.TotalHeigh = 487;
  hltdc.Init.Backcolor.Blue = 0;
  hltdc.Init.Backcolor.Green = 0;
  hltdc.Init.Backcolor.Red = 0;
  if (HAL_LTDC_Init(&hltdc) != HAL_OK)
  {
    Error_Handler();
  }
  pLayerCfg.WindowX0 = 0;
  pLayerCfg.WindowX1 = 0;
  pLayerCfg.WindowY0 = 0;
  pLayerCfg.WindowY1 = 0;
  pLayerCfg.PixelFormat = LTDC_PIXEL_FORMAT_ARGB8888;
  pLayerCfg.Alpha = 0;
  pLayerCfg.Alpha0 = 0;
  pLayerCfg.BlendingFactor1 = LTDC_BLENDING_FACTOR1_CA;
  pLayerCfg.BlendingFactor2 = LTDC_BLENDING_FACTOR2_CA;
  pLayerCfg.FBStartAdress = 0;
  pLayerCfg.ImageWidth = 0;
  pLayerCfg.ImageHeight = 0;
  pLayerCfg.Backcolor.Blue = 0;
  pLayerCfg.Backcolor.Green = 0;
  pLayerCfg.Backcolor.Red = 0;
  if (HAL_LTDC_ConfigLayer(&hltdc, &pLayerCfg, 0) != HAL_OK)
  {
    Error_Handler();
  }
  pLayerCfg1.WindowX0 = 0;
  pLayerCfg1.WindowX1 = 0;
  pLayerCfg1.WindowY0 = 0;
  pLayerCfg1.WindowY1 = 0;
  pLayerCfg1.PixelFormat = LTDC_PIXEL_FORMAT_ARGB8888;
  pLayerCfg1.Alpha = 0;
  pLayerCfg1.Alpha0 = 0;
  pLayerCfg1.BlendingFactor1 = LTDC_BLENDING_FACTOR1_CA;
  pLayerCfg1.BlendingFactor2 = LTDC_BLENDING_FACTOR2_CA;
  pLayerCfg1.FBStartAdress = 0;
  pLayerCfg1.ImageWidth = 0;
  pLayerCfg1.ImageHeight = 0;
  pLayerCfg1.Backcolor.Blue = 0;
  pLayerCfg1.Backcolor.Green = 0;
  pLayerCfg1.Backcolor.Red = 0;
  if (HAL_LTDC_ConfigLayer(&hltdc, &pLayerCfg1, 1) != HAL_OK)
  {
    Error_Handler();
  }

}

static void MX_QUADSPI_Init(void)
{

  /* QUADSPI parameter configuration*/
  hqspi.Instance = QUADSPI;
  hqspi.Init.ClockPrescaler = 1;
  hqspi.Init.FifoThreshold = 1;
  hqspi.Init.SampleShifting = QSPI_SAMPLE_SHIFTING_HALFCYCLE;
  hqspi.Init.FlashSize = 27;
  hqspi.Init.ChipSelectHighTime = QSPI_CS_HIGH_TIME_5_CYCLE;
  hqspi.Init.ClockMode = QSPI_CLOCK_MODE_0;
  hqspi.Init.FlashID = QSPI_FLASH_ID_1;
  hqspi.Init.DualFlash = QSPI_DUALFLASH_DISABLE;
  if (HAL_QSPI_Init(&hqspi) != HAL_OK)
  {
    Error_Handler();
  }

}

static void MX_TIM2_Init(void)
{

  TIM_ClockConfigTypeDef sClockSourceConfig = {0};
  TIM_MasterConfigTypeDef sMasterConfig = {0};
  TIM_OC_InitTypeDef sConfigOC = {0};

  htim2.Instance = TIM2;
  htim2.Init.Prescaler = 180-1;
  htim2.Init.CounterMode = TIM_COUNTERMODE_UP;
  htim2.Init.Period = 50;
  htim2.Init.ClockDivision = TIM_CLOCKDIVISION_DIV1;
  htim2.Init.AutoReloadPreload = TIM_AUTORELOAD_PRELOAD_DISABLE;
  if (HAL_TIM_Base_Init(&htim2) != HAL_OK)
  {
    Error_Handler();
  }
  sClockSourceConfig.ClockSource = TIM_CLOCKSOURCE_INTERNAL;
  if (HAL_TIM_ConfigClockSource(&htim2, &sClockSourceConfig) != HAL_OK)
  {
    Error_Handler();
  }
  if (HAL_TIM_PWM_Init(&htim2) != HAL_OK)
  {
    Error_Handler();
  }
  sMasterConfig.MasterOutputTrigger = TIM_TRGO_RESET;
  sMasterConfig.MasterSlaveMode = TIM_MASTERSLAVEMODE_DISABLE;
  if (HAL_TIMEx_MasterConfigSynchronization(&htim2, &sMasterConfig) != HAL_OK)
  {
    Error_Handler();
  }
  sConfigOC.OCMode = TIM_OCMODE_PWM1;
  sConfigOC.Pulse = 0;
  sConfigOC.OCPolarity = TIM_OCPOLARITY_HIGH;
  sConfigOC.OCFastMode = TIM_OCFAST_DISABLE;
  if (HAL_TIM_PWM_ConfigChannel(&htim2, &sConfigOC, TIM_CHANNEL_3) != HAL_OK)
  {
    Error_Handler();
  }
  HAL_TIM_MspPostInit(&htim2);

}

/* FMC initialization function */
static void MX_FMC_Init(void)
{

  FMC_SDRAM_TimingTypeDef SdramTiming = {0};

  /** Perform the SDRAM1 memory initialization sequence
  */
  hsdram1.Instance = FMC_SDRAM_DEVICE;
  /* hsdram1.Init */
  hsdram1.Init.SDBank = FMC_SDRAM_BANK1;
  hsdram1.Init.ColumnBitsNumber = FMC_SDRAM_COLUMN_BITS_NUM_8;
  hsdram1.Init.RowBitsNumber = FMC_SDRAM_ROW_BITS_NUM_12;
  hsdram1.Init.MemoryDataWidth = FMC_SDRAM_MEM_BUS_WIDTH_32;
  hsdram1.Init.InternalBankNumber = FMC_SDRAM_INTERN_BANKS_NUM_4;
  hsdram1.Init.CASLatency = FMC_SDRAM_CAS_LATENCY_1;
  hsdram1.Init.WriteProtection = FMC_SDRAM_WRITE_PROTECTION_DISABLE;
  hsdram1.Init.SDClockPeriod = FMC_SDRAM_CLOCK_DISABLE;
  hsdram1.Init.ReadBurst = FMC_SDRAM_RBURST_DISABLE;
  hsdram1.Init.ReadPipeDelay = FMC_SDRAM_RPIPE_DELAY_0;
  /* SdramTiming */
  SdramTiming.LoadToActiveDelay = 16;
  SdramTiming.ExitSelfRefreshDelay = 16;
  SdramTiming.SelfRefreshTime = 16;
  SdramTiming.RowCycleDelay = 16;
  SdramTiming.WriteRecoveryTime = 16;
  SdramTiming.RPDelay = 16;
  SdramTiming.RCDDelay = 16;

  if (HAL_SDRAM_Init(&hsdram1, &SdramTiming) != HAL_OK)
  {
    Error_Handler( );
  }

}

static void MX_GPIO_Init(void)
{
  GPIO_InitTypeDef GPIO_InitStruct = {0};

  /* GPIO Ports Clock Enable */
  __HAL_RCC_GPIOE_CLK_ENABLE();
  __HAL_RCC_GPIOB_CLK_ENABLE();
  __HAL_RCC_GPIOG_CLK_ENABLE();
  __HAL_RCC_GPIOD_CLK_ENABLE();
  __HAL_RCC_GPIOI_CLK_ENABLE();
  __HAL_RCC_GPIOF_CLK_ENABLE();
  __HAL_RCC_GPIOK_CLK_ENABLE();
  __HAL_RCC_GPIOH_CLK_ENABLE();
  __HAL_RCC_GPIOC_CLK_ENABLE();
  __HAL_RCC_GPIOJ_CLK_ENABLE();
  __HAL_RCC_GPIOA_CLK_ENABLE();

  /*Configure GPIO pin Output Level */
  HAL_GPIO_WritePin(GPIOD, LED3_Pin|LED2_Pin, GPIO_PIN_RESET);

  /*Configure GPIO pin Output Level */
  HAL_GPIO_WritePin(LED4_GPIO_Port, LED4_Pin, GPIO_PIN_RESET);

  /*Configure GPIO pin Output Level */
  HAL_GPIO_WritePin(LED1_GPIO_Port, LED1_Pin, GPIO_PIN_RESET);

  /*Configure GPIO pin Output Level */
  HAL_GPIO_WritePin(GPIOH, GPIO_PIN_7, GPIO_PIN_RESET);

  /*Configure GPIO pin Output Level */
  HAL_GPIO_WritePin(LCD_BL_CTRL_GPIO_Port, LCD_BL_CTRL_Pin, GPIO_PIN_RESET);

  /*Configure GPIO pin Output Level */
  HAL_GPIO_WritePin(GPIOB, EXT_RESET_Pin|SPEED_LOW_Pin|SPEED_HIGH_Pin, GPIO_PIN_RESET);

  /*Configure GPIO pins : LED3_Pin LED2_Pin */
  GPIO_InitStruct.Pin = LED3_Pin|LED2_Pin;
  GPIO_InitStruct.Mode = GPIO_MODE_OUTPUT_OD;
  GPIO_InitStruct.Pull = GPIO_NOPULL;
  GPIO_InitStruct.Speed = GPIO_SPEED_FREQ_LOW;
  HAL_GPIO_Init(GPIOD, &GPIO_InitStruct);

  /*Configure GPIO pin : LED4_Pin */
  GPIO_InitStruct.Pin = LED4_Pin;
  GPIO_InitStruct.Mode = GPIO_MODE_OUTPUT_OD;
  GPIO_InitStruct.Pull = GPIO_NOPULL;
  GPIO_InitStruct.Speed = GPIO_SPEED_FREQ_LOW;
  HAL_GPIO_Init(LED4_GPIO_Port, &GPIO_InitStruct);

  /*Configure GPIO pin : LED1_Pin */
  GPIO_InitStruct.Pin = LED1_Pin;
  GPIO_InitStruct.Mode = GPIO_MODE_OUTPUT_OD;
  GPIO_InitStruct.Pull = GPIO_NOPULL;
  GPIO_InitStruct.Speed = GPIO_SPEED_FREQ_LOW;
  HAL_GPIO_Init(LED1_GPIO_Port, &GPIO_InitStruct);

  /*Configure GPIO pin : LCD_INT_Pin */
  GPIO_InitStruct.Pin = LCD_INT_Pin;
  GPIO_InitStruct.Mode = GPIO_MODE_IT_RISING;
  GPIO_InitStruct.Pull = GPIO_NOPULL;
  HAL_GPIO_Init(LCD_INT_GPIO_Port, &GPIO_InitStruct);

  /*Configure GPIO pin : PH7 */
  GPIO_InitStruct.Pin = GPIO_PIN_7;
  GPIO_InitStruct.Mode = GPIO_MODE_OUTPUT_PP;
  GPIO_InitStruct.Pull = GPIO_NOPULL;
  GPIO_InitStruct.Speed = GPIO_SPEED_FREQ_LOW;
  HAL_GPIO_Init(GPIOH, &GPIO_InitStruct);

  /*Configure GPIO pin : LCD_BL_CTRL_Pin */
  GPIO_InitStruct.Pin = LCD_BL_CTRL_Pin;
  GPIO_InitStruct.Mode = GPIO_MODE_OUTPUT_PP;
  GPIO_InitStruct.Pull = GPIO_NOPULL;
  GPIO_InitStruct.Speed = GPIO_SPEED_FREQ_LOW;
  HAL_GPIO_Init(LCD_BL_CTRL_GPIO_Port, &GPIO_InitStruct);

  /*Configure GPIO pins : EXT_RESET_Pin SPEED_LOW_Pin SPEED_HIGH_Pin */
  GPIO_InitStruct.Pin = EXT_RESET_Pin|SPEED_LOW_Pin|SPEED_HIGH_Pin;
  GPIO_InitStruct.Mode = GPIO_MODE_OUTPUT_PP;
  GPIO_InitStruct.Pull = GPIO_NOPULL;
  GPIO_InitStruct.Speed = GPIO_SPEED_FREQ_LOW;
  HAL_GPIO_Init(GPIOB, &GPIO_InitStruct);

}

void StartDefaultTask(void const * argument)
{
  /* USER CODE BEGIN 5 */
  /* Infinite loop */
  for(;;)
  {
    osDelay(1);
    lv_task_handler();
  }
  /* USER CODE END 5 */
}

void HAL_TIM_PeriodElapsedCallback(TIM_HandleTypeDef *htim)
{
  if (htim->Instance == TIM6) {
    HAL_IncTick();
    lv_tick_inc(1);
  }
}

void Error_Handler(void)
{
  __disable_irq();
  while (1)
  {
  }
}

/************************ (C) COPYRIGHT STMicroelectronics *****END OF FILE****/
